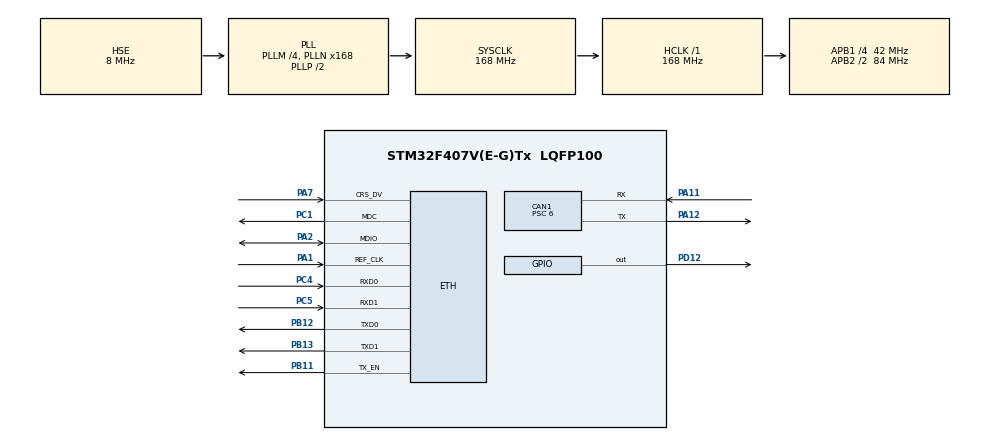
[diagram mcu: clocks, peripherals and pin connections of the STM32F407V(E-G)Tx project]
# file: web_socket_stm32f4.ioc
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CAN1.ABOM=ENABLE
CAN1.BS1=CAN_BS1_11TQ
CAN1.BS2=CAN_BS2_2TQ
CAN1.CalculateBaudRate=500000
CAN1.CalculateTimeBit=1999.99
CAN1.CalculateTimeQuantum=142.85714285714286
CAN1.Prescaler=6
CAN1.TXFP=ENABLE
ETH.MediaInterface=ETH_MEDIA_INTERFACE_RMII
ETH.PhyAddress=0
FREERTOS.INCLUDE_eTaskGetState=1
FREERTOS.INCLUDE_vTaskCleanUpResources=1
FREERTOS.INCLUDE_xTaskGetHandle=1
FREERTOS.Tasks01=MainTask,0,128,thread_MainTask,Default,NULL,Dynamic,NULL,NULL;SecondTask,0,128,thread_SecondTask,Default,NULL,Dynamic,NULL,NULL
FREERTOS.configTOTAL_HEAP_SIZE=30720
FREERTOS.configUSE_COUNTING_SEMAPHORES=1
LWIP.IP_ADDRESS=192.168.000.007
LWIP.LWIP_DHCP=0
LWIP.MEMP_NUM_NETBUF=4
LWIP.MEMP_NUM_NETCONN=8
LWIP.NETMASK_ADDRESS=255.255.255.000
LWIP.Version=v2.1.2_Cube
MBEDTLS.MBEDTLS_AES_C=0
MBEDTLS.MBEDTLS_AES_ROM_TABLES=0
MBEDTLS.MBEDTLS_ASN1_PARSE_C=0
MBEDTLS.MBEDTLS_ASN1_WRITE_C=0
MBEDTLS.MBEDTLS_BIGNUM_C=0
MBEDTLS.MBEDTLS_CAMELLIA_C=0
MBEDTLS.MBEDTLS_CERTS_C=0
MBEDTLS.MBEDTLS_CHACHA20_C=0
MBEDTLS.MBEDTLS_CIPHER_C=0
MBEDTLS.MBEDTLS_CIPHER_MODE_OFB=0
MBEDTLS.MBEDTLS_CIPHER_MODE_XTS=0
MBEDTLS.MBEDTLS_ECP_DP_CURVE448_ENABLED=0
MBEDTLS.MBEDTLS_ECP_DP_SECP256R1_ENABLED=0
MBEDTLS.MBEDTLS_ECP_DP_SECP384R1_ENABLED=0
MBEDTLS.MBEDTLS_ECP_NIST_OPTIM=0
MBEDTLS.MBEDTLS_ENTROPY_C=0
MBEDTLS.MBEDTLS_HAVE_ASM=0
MBEDTLS.MBEDTLS_HAVE_TIME=0
MBEDTLS.MBEDTLS_HKDF_C=0
MBEDTLS.MBEDTLS_MD_C=0
MBEDTLS.MBEDTLS_NET_C=0
MBEDTLS.MBEDTLS_NO_DEFAULT_ENTROPY_SOURCES=0
MBEDTLS.MBEDTLS_NO_PLATFORM_ENTROPY=0
MBEDTLS.MBEDTLS_NO_UDBL_DIVISION=0
MBEDTLS.MBEDTLS_OID_C=0
MBEDTLS.MBEDTLS_PEM_PARSE_C=0
MBEDTLS.MBEDTLS_PK_PARSE_C=0
MBEDTLS.MBEDTLS_PLATFORM_C=0
MBEDTLS.MBEDTLS_POLY1305_C=0
MBEDTLS.MBEDTLS_REMOVE_3DES_CIPHERSUITES=0
MBEDTLS.MBEDTLS_SHA1_C=1
MBEDTLS.MBEDTLS_SHA256_C=0
MBEDTLS.MBEDTLS_SHA512_C=0
MBEDTLS.MBEDTLS_SSL_CLI_C=0
MBEDTLS.MBEDTLS_SSL_SRV_C=0
Mcu.Family=STM32F4
Mcu.Name=STM32F407V(E-G)Tx
Mcu.Package=LQFP100
NVIC.CAN1_RX0_IRQn=true\:5\:0\:false\:false\:true\:true\:true\:true
NVIC.ETH_IRQn=true\:5\:0\:false\:false\:true\:false\:false\:true
NVIC.PriorityGroup=NVIC_PRIORITYGROUP_4
NVIC.TIM1_UP_TIM10_IRQn=true\:0\:0\:false\:false\:true\:false\:false\:true
NVIC.TimeBase=TIM1_UP_TIM10_IRQn
NVIC.TimeBaseIP=TIM1
PA1.Mode=RMII
PA1.Signal=ETH_REF_CLK
PA11.Mode=CAN_Activate
PA11.Signal=CAN1_RX
PA12.Mode=CAN_Activate
PA12.Signal=CAN1_TX
PA13.Mode=Trace_Asynchronous_SW
PA13.Signal=SYS_JTMS-SWDIO
PA14.Mode=Trace_Asynchronous_SW
PA14.Signal=SYS_JTCK-SWCLK
PA2.Mode=RMII
PA2.Signal=ETH_MDIO
PA7.Mode=RMII
PA7.Signal=ETH_CRS_DV
PB11.Mode=RMII
PB11.Signal=ETH_TX_EN
PB12.Mode=RMII
PB12.Signal=ETH_TXD0
PB13.Mode=RMII
PB13.Signal=ETH_TXD1
PB3.Mode=Trace_Asynchronous_SW
PB3.Signal=SYS_JTDO-SWO
PC1.Mode=RMII
PC1.Signal=ETH_MDC
PC4.Mode=RMII
PC4.Signal=ETH_RXD0
PC5.Mode=RMII
PC5.Signal=ETH_RXD1
PD12.Signal=GPIO_Output
PH0-OSC_IN.Mode=HSE-External-Oscillator
PH0-OSC_IN.Signal=RCC_OSC_IN
PH1-OSC_OUT.Mode=HSE-External-Oscillator
PH1-OSC_OUT.Signal=RCC_OSC_OUT
ProjectManager.HeapSize=0x2000
ProjectManager.StackSize=0x4000
ProjectManager.TargetToolchain=MDK-ARM V5
RCC.48MHZClocksFreq_Value=48000000
RCC.AHBFreq_Value=168000000
RCC.APB1CLKDivider=RCC_HCLK_DIV4
RCC.APB1Freq_Value=42000000
RCC.APB1TimFreq_Value=84000000
RCC.APB2CLKDivider=RCC_HCLK_DIV2
RCC.APB2Freq_Value=84000000
RCC.APB2TimFreq_Value=168000000
RCC.CortexFreq_Value=168000000
RCC.HCLKFreq_Value=168000000
RCC.HSE_VALUE=8000000
RCC.HSI_VALUE=16000000
RCC.LSE_VALUE=32768
RCC.PLLM=4
RCC.PLLN=168
RCC.PLLQ=7
RCC.PLLSourceVirtual=RCC_PLLSOURCE_HSE
RCC.SYSCLKFreq_VALUE=168000000
RCC.SYSCLKSource=RCC_SYSCLKSOURCE_PLLCLK
RCC.VCOOutputFreq_Value=336000000
VP_FREERTOS_VS_CMSIS_V1.Mode=CMSIS_V1
VP_LWIP_VS_Enabled.Mode=Enabled
VP_MBEDTLS_VS_MBEDTLS.Mode=Enabled
VP_RNG_VS_RNG.Mode=RNG_Activate
VP_SYS_VS_tim1.Mode=TIM1
board=custom

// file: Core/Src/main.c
/* USER CODE BEGIN Header */
/**
  ******************************************************************************
  * @file           : main.c
  * @brief          : Main program body
  ******************************************************************************
  * @attention
  *
  * <h2><center>&copy; Copyright (c) 2021 STMicroelectronics.
  * All rights reserved.</center></h2>
  *
  * This software component is licensed by ST under Ultimate Liberty license
  * SLA0044, the "License"; You may not use this file except in compliance with
  * the License. You may obtain a copy of the License at:
  *                             www.st.com/SLA0044
  *
  ******************************************************************************
  */
/* USER CODE END Header */
#include "main.h"
#include "cmsis_os.h"
#include "can.h"
#include "mbedtls.h"
#include "rng.h"
#include "gpio.h"

void SystemClock_Config(void);
void MX_FREERTOS_Init(void);

int main(void)
{

  /* MCU Configuration--------------------------------------------------------*/

  /* Reset of all peripherals, Initializes the Flash interface and the Systick. */
  HAL_Init();

  /* Configure the system clock */
  SystemClock_Config();

  /* Initialize all configured peripherals */
  MX_GPIO_Init();
  MX_MBEDTLS_Init();
  MX_CAN1_Init();
  MX_RNG_Init();

  /* Call init function for freertos objects (in freertos.c) */
  MX_FREERTOS_Init();
  /* Start scheduler */
  osKernelStart();

  /* We should never get here as control is now taken by the scheduler */
  /* Infinite loop */
  while (1)
  {

  }
}

void SystemClock_Config(void)
{
  RCC_OscInitTypeDef RCC_OscInitStruct = {0};
  RCC_ClkInitTypeDef RCC_ClkInitStruct = {0};

  /** Configure the main internal regulator output voltage
  */
  __HAL_RCC_PWR_CLK_ENABLE();
  __HAL_PWR_VOLTAGESCALING_CONFIG(PWR_REGULATOR_VOLTAGE_SCALE1);
  /** Initializes the RCC Oscillators according to the specified parameters
  * in the RCC_OscInitTypeDef structure.
  */
  RCC_OscInitStruct.OscillatorType = RCC_OSCILLATORTYPE_HSE;
  RCC_OscInitStruct.HSEState = RCC_HSE_ON;
  RCC_OscInitStruct.PLL.PLLState = RCC_PLL_ON;
  RCC_OscInitStruct.PLL.PLLSource = RCC_PLLSOURCE_HSE;
  RCC_OscInitStruct.PLL.PLLM = 4;
  RCC_OscInitStruct.PLL.PLLN = 168;
  RCC_OscInitStruct.PLL.PLLP = RCC_PLLP_DIV2;
  RCC_OscInitStruct.PLL.PLLQ = 7;
  if (HAL_RCC_OscConfig(&RCC_OscInitStruct) != HAL_OK)
  {
    Error_Handler();
  }
  /** Initializes the CPU, AHB and APB buses clocks
  */
  RCC_ClkInitStruct.ClockType = RCC_CLOCKTYPE_HCLK|RCC_CLOCKTYPE_SYSCLK
                              |RCC_CLOCKTYPE_PCLK1|RCC_CLOCKTYPE_PCLK2;
  RCC_ClkInitStruct.SYSCLKSource = RCC_SYSCLKSOURCE_PLLCLK;
  RCC_ClkInitStruct.AHBCLKDivider = RCC_SYSCLK_DIV1;
  RCC_ClkInitStruct.APB1CLKDivider = RCC_HCLK_DIV4;
  RCC_ClkInitStruct.APB2CLKDivider = RCC_HCLK_DIV2;

  if (HAL_RCC_ClockConfig(&RCC_ClkInitStruct, FLASH_LATENCY_5) != HAL_OK)
  {
    Error_Handler();
  }
}

 /**
  * @brief  Period elapsed callback in non blocking mode
  * @note   This function is called  when TIM1 interrupt took place, inside
  * HAL_TIM_IRQHandler(). It makes a direct call to HAL_IncTick() to increment
  * a global variable "uwTick" used as application time base.
  * @param  htim : TIM handle
  * @retval None
  */
void HAL_TIM_PeriodElapsedCallback(TIM_HandleTypeDef *htim)
{
  if (htim->Instance == TIM1) {
    HAL_IncTick();
  }
}

void Error_Handler(void)
{
}

/************************ (C) COPYRIGHT STMicroelectronics *****END OF FILE****/

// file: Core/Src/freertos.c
/* USER CODE BEGIN Header */
/**
  ******************************************************************************
  * File Name          : freertos.c
  * Description        : Code for freertos applications
  ******************************************************************************
  * @attention
  *
  * <h2><center>&copy; Copyright (c) 2021 STMicroelectronics.
  * All rights reserved.</center></h2>
  *
  * This software component is licensed by ST under Ultimate Liberty license
  * SLA0044, the "License"; You may not use this file except in compliance with
  * the License. You may obtain a copy of the License at:
  *                             www.st.com/SLA0044
  *
  ******************************************************************************
  */
/* USER CODE END Header */

#include "FreeRTOS.h"
#include "task.h"
#include "main.h"
#include "cmsis_os.h"

/* USER CODE BEGIN Includes */
#include "rng.h"
#include "http.h"
#include "websocket.h"
/* USER CODE END Includes */

/* USER CODE BEGIN Variables */
extern http_server_t http_server;
extern ws_server_t ws_server;
/* USER CODE END Variables */
osThreadId MainTaskHandle;
osThreadId SecondTaskHandle;

void thread_MainTask(void const * argument);
void thread_SecondTask(void const * argument);

extern void MX_LWIP_Init(void);
void MX_FREERTOS_Init(void); /* (MISRA C 2004 rule 8.1) */

/* GetIdleTaskMemory prototype (linked to static allocation support) */
void vApplicationGetIdleTaskMemory( StaticTask_t **ppxIdleTaskTCBBuffer, StackType_t **ppxIdleTaskStackBuffer, uint32_t *pulIdleTaskStackSize );

/* USER CODE BEGIN GET_IDLE_TASK_MEMORY */
static StaticTask_t xIdleTaskTCBBuffer;
static StackType_t xIdleStack[configMINIMAL_STACK_SIZE];

void vApplicationGetIdleTaskMemory( StaticTask_t **ppxIdleTaskTCBBuffer, StackType_t **ppxIdleTaskStackBuffer, uint32_t *pulIdleTaskStackSize )
{
  *ppxIdleTaskTCBBuffer = &xIdleTaskTCBBuffer;
  *ppxIdleTaskStackBuffer = &xIdleStack[0];
  *pulIdleTaskStackSize = configMINIMAL_STACK_SIZE;
  /* place for user code */
}
/* USER CODE END GET_IDLE_TASK_MEMORY */

void MX_FREERTOS_Init(void) {

  /* Create the thread(s) */
  /* definition and creation of MainTask */
  osThreadDef(MainTask, thread_MainTask, osPriorityNormal, 0, 128);
  MainTaskHandle = osThreadCreate(osThread(MainTask), NULL);

  /* definition and creation of SecondTask */
  osThreadDef(SecondTask, thread_SecondTask, osPriorityNormal, 0, 128);
  SecondTaskHandle = osThreadCreate(osThread(SecondTask), NULL);

}

void thread_MainTask(void const * argument)
{
  /* USER CODE BEGIN thread_MainTask */
  MX_LWIP_Init();
  /** Get a cont files of website and make site catalogue */
  if (http_create_filesystem(&http_server.file_system) == 0)
  {
    /** Create new token and start http server */
    uint32_t new_token = 0;
    HAL_RNG_GenerateRandomNumber(&hrng, &new_token);
    sprintf(http_server.token, "%x", new_token);
    sys_thread_new("HTTP", http_server_task, (void*)&http_server, 1024, osPriorityNormal);
  }
  sys_thread_new("WS", ws_server_task, (void*)&ws_server, 1024, osPriorityNormal);

  /* Infinite loop */
  for(;;)
  {
    osDelay(100);
  }
  /* USER CODE END thread_MainTask */
}

void thread_SecondTask(void const * argument)
{
  /* USER CODE BEGIN thread_SecondTask */
  /* Infinite loop */
  for(;;)
  {
    osDelay(100);
  }
  /* USER CODE END thread_SecondTask */
}

/************************ (C) COPYRIGHT STMicroelectronics *****END OF FILE****/
